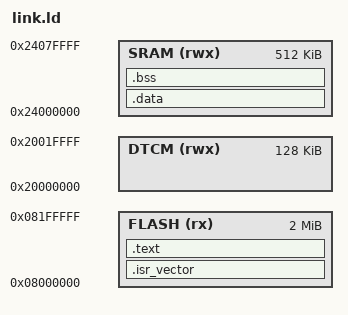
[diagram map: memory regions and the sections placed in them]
/*
 * link.ld — linker script for STM32H743 RadarPhantom firmware
 *
 * Author: jayis1
 * License: GPL-2.0
 *
 * Places code in flash (0x08000000, 2 MB) and data/bss in DTCM/SRAM.
 */
ENTRY(Reset_Handler)

MEMORY
{
    FLASH (rx)  : ORIGIN = 0x08000000, LENGTH = 2048K
    DTCM  (rwx) : ORIGIN = 0x20000000, LENGTH = 128K
    SRAM  (rwx) : ORIGIN = 0x24000000, LENGTH = 512K
}

_estack = ORIGIN(DTCM) + LENGTH(DTCM);

SECTIONS
{
    .isr_vector : {
        KEEP(*(.isr_vector))
    } > FLASH

    .text : {
        *(.text)
        *(.text*)
        *(.rodata)
        *(.rodata*)
        . = ALIGN(4);
        _etext = .;
    } > FLASH

    .data : AT (_etext) {
        _sidata = LOADADDR(.data);
        _sdata = .;
        *(.data)
        *(.data*)
        . = ALIGN(4);
        _edata = .;
    } > SRAM

    .bss : {
        _sbss = .;
        *(.bss)
        *(.bss*)
        *(COMMON)
        . = ALIGN(4);
        _ebss = .;
    } > SRAM

    /DISCARD/ : {
        *(.ARM.exidx*)
        *(.comment)
    }
}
